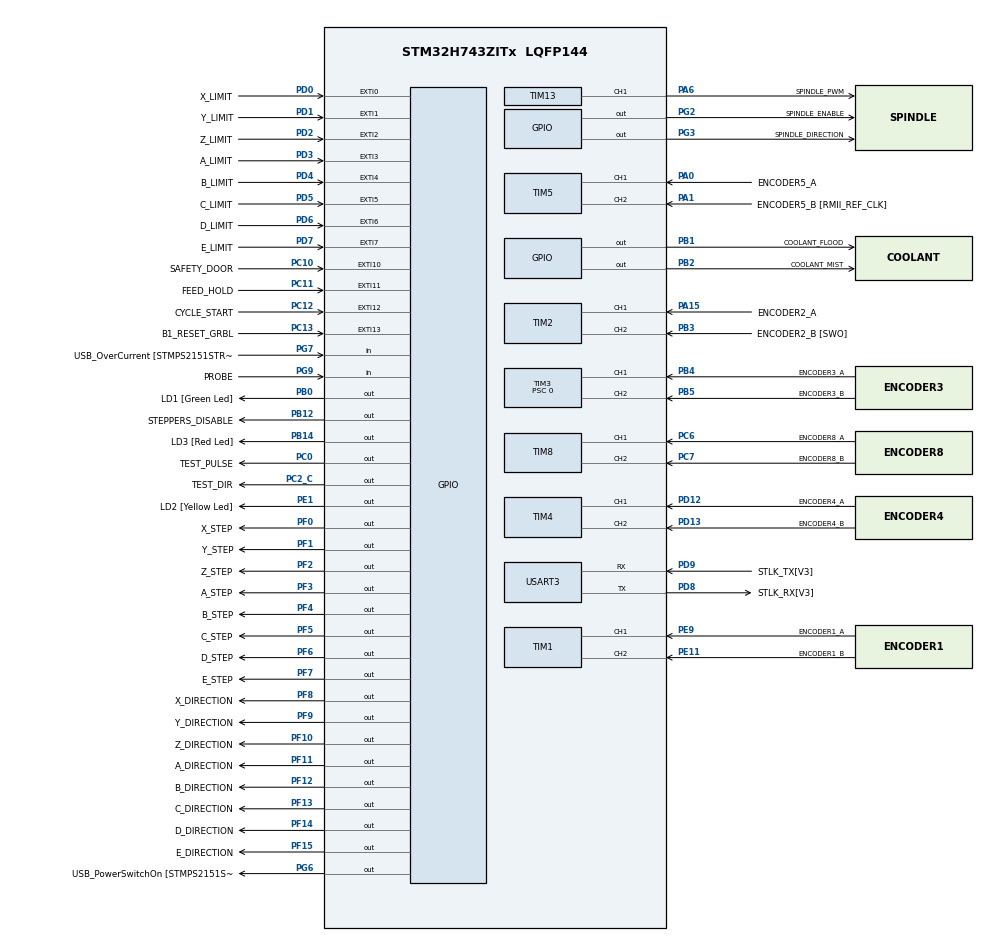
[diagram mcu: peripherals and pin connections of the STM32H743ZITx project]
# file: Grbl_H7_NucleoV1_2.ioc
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CORTEX_M7.AccessPermission-Cortex_Memory_Protection_Unit_Region0_Settings=MPU_REGION_PRIV_RW_URO
CORTEX_M7.BaseAddress-Cortex_Memory_Protection_Unit_Region0_Settings=0x38800000
CORTEX_M7.CPU_DCache=Enabled
CORTEX_M7.CPU_ICache=Enabled
CORTEX_M7.Enable-Cortex_Memory_Protection_Unit_Region0_Settings=MPU_REGION_ENABLE
CORTEX_M7.IsBufferable-Cortex_Memory_Protection_Unit_Region0_Settings=MPU_ACCESS_BUFFERABLE
CORTEX_M7.IsCacheable-Cortex_Memory_Protection_Unit_Region0_Settings=MPU_ACCESS_CACHEABLE
CORTEX_M7.IsShareable-Cortex_Memory_Protection_Unit_Region0_Settings=MPU_ACCESS_SHAREABLE
CORTEX_M7.MPU_Control=MPU_HFNMI_PRIVDEF
CORTEX_M7.Size-Cortex_Memory_Protection_Unit_Region0_Settings=MPU_REGION_SIZE_4KB
Mcu.Family=STM32H7
Mcu.Name=STM32H743ZITx
Mcu.Package=LQFP144
NVIC.EXTI0_IRQn=true\:1\:0\:true\:false\:true\:true\:true
NVIC.EXTI15_10_IRQn=true\:8\:0\:true\:false\:true\:true\:true
NVIC.EXTI1_IRQn=true\:1\:0\:true\:false\:true\:true\:true
NVIC.EXTI2_IRQn=true\:1\:0\:true\:false\:true\:true\:true
NVIC.EXTI3_IRQn=true\:1\:0\:true\:false\:true\:true\:true
NVIC.EXTI4_IRQn=true\:1\:0\:true\:false\:true\:true\:true
NVIC.EXTI9_5_IRQn=true\:1\:0\:true\:false\:true\:true\:true
NVIC.PriorityGroup=NVIC_PRIORITYGROUP_4
NVIC.RCC_IRQn=true\:0\:0\:true\:false\:true\:true\:false
NVIC.TIM1_UP_IRQn=true\:0\:0\:true\:false\:true\:true\:true
NVIC.TIM3_IRQn=true\:0\:0\:true\:false\:true\:true\:true
NVIC.TIM4_IRQn=true\:0\:0\:false\:false\:true\:true\:true
NVIC.TIM8_BRK_TIM12_IRQn=true\:6\:0\:true\:false\:true\:true\:true
NVIC.TIM8_TRG_COM_TIM14_IRQn=true\:5\:0\:true\:false\:true\:true\:true
NVIC.TIM8_UP_TIM13_IRQn=true\:0\:0\:false\:false\:true\:true\:true
NVIC.USART3_IRQn=true\:7\:0\:true\:false\:true\:true\:true
PA0.GPIO_Label=ENCODER5_A
PA0.GPIO_PuPd=GPIO_PULLUP
PA0.GPIO_Speed=GPIO_SPEED_FREQ_VERY_HIGH
PA0.Signal=S_TIM5_CH1
PA1.GPIO_Label=ENCODER5_B [RMII_REF_CLK]
PA1.GPIO_PuPd=GPIO_PULLUP
PA1.GPIO_Speed=GPIO_SPEED_FREQ_VERY_HIGH
PA1.Signal=S_TIM5_CH2
PA10.GPIO_Label=USB_ID
PA10.Signal=USB_OTG_FS_ID
PA11.GPIO_Label=USB_DM
PA11.GPIO_Speed=GPIO_SPEED_FREQ_VERY_HIGH
PA11.Signal=USB_OTG_FS_DM
PA12.GPIO_Label=USB_DP
PA12.GPIO_Speed=GPIO_SPEED_FREQ_VERY_HIGH
PA12.Signal=USB_OTG_FS_DP
PA13\ (JTMS/SWDIO).Mode=Serial_Wire
PA13\ (JTMS/SWDIO).Signal=DEBUG_JTMS-SWDIO
PA14\ (JTCK/SWCLK).Mode=Serial_Wire
PA14\ (JTCK/SWCLK).Signal=DEBUG_JTCK-SWCLK
PA15\ (JTDI).GPIO_Label=ENCODER2_A
PA15\ (JTDI).GPIO_PuPd=GPIO_PULLUP
PA15\ (JTDI).GPIO_Speed=GPIO_SPEED_FREQ_VERY_HIGH
PA15\ (JTDI).Signal=S_TIM2_CH1
PA2.GPIO_Label=RMII_MDIO
PA2.Signal=ETH_MDIO
PA6.GPIO_Label=SPINDLE_PWM
PA6.GPIO_Speed=GPIO_SPEED_FREQ_VERY_HIGH
PA6.Signal=S_TIM13_CH1
PA7.GPIO_Label=RMII_CRS_DV
PA7.Signal=ETH_CRS_DV
PA8.GPIO_Label=USB_SOF [TP1]
PA8.GPIO_Speed=GPIO_SPEED_FREQ_VERY_HIGH
PA8.Signal=USB_OTG_FS_SOF
PA9.GPIO_Label=USB_VBUS
PA9.Signal=USB_OTG_FS_VBUS
PB0.GPIO_Label=LD1 [Green Led]
PB0.GPIO_Speed=GPIO_SPEED_FREQ_VERY_HIGH
PB0.Signal=GPIO_Output
PB1.GPIO_Label=COOLANT_FLOOD
PB1.GPIO_Speed=GPIO_SPEED_FREQ_VERY_HIGH
PB1.Signal=GPIO_Output
PB12.GPIO_Label=STEPPERS_DISABLE
PB12.GPIO_Speed=GPIO_SPEED_FREQ_VERY_HIGH
PB12.Signal=GPIO_Output
PB13.GPIO_Label=RMII_TXD1
PB13.Signal=ETH_TXD1
PB14.GPIO_Label=LD3 [Red Led]
PB14.GPIO_Speed=GPIO_SPEED_FREQ_VERY_HIGH
PB14.Signal=GPIO_Output
PB2.GPIO_Label=COOLANT_MIST
PB2.GPIO_Speed=GPIO_SPEED_FREQ_VERY_HIGH
PB2.Signal=GPIO_Output
PB3\ (JTDO/TRACESWO).GPIO_Label=ENCODER2_B [SWO]
PB3\ (JTDO/TRACESWO).GPIO_PuPd=GPIO_PULLUP
PB3\ (JTDO/TRACESWO).GPIO_Speed=GPIO_SPEED_FREQ_VERY_HIGH
PB3\ (JTDO/TRACESWO).Signal=S_TIM2_CH2
PB4\ (NJTRST).GPIO_Label=ENCODER3_A
PB4\ (NJTRST).GPIO_PuPd=GPIO_PULLUP
PB4\ (NJTRST).GPIO_Speed=GPIO_SPEED_FREQ_VERY_HIGH
PB4\ (NJTRST).Signal=S_TIM3_CH1
PB5.GPIO_Label=ENCODER3_B
PB5.GPIO_PuPd=GPIO_PULLUP
PB5.GPIO_Speed=GPIO_SPEED_FREQ_VERY_HIGH
PB5.Signal=S_TIM3_CH2
PC0.GPIO_Label=TEST_PULSE
PC0.GPIO_Speed=GPIO_SPEED_FREQ_VERY_HIGH
PC0.Signal=GPIO_Output
PC1.GPIO_Label=RMII_MDC
PC1.Signal=ETH_MDC
PC10.GPIO_Label=SAFETY_DOOR
PC10.GPIO_ModeDefaultEXTI=GPIO_MODE_IT_FALLING
PC10.GPIO_PuPd=GPIO_PULLUP
PC10.Signal=GPXTI10
PC11.GPIO_Label=FEED_HOLD
PC11.GPIO_ModeDefaultEXTI=GPIO_MODE_IT_FALLING
PC11.GPIO_PuPd=GPIO_PULLUP
PC11.Signal=GPXTI11
PC12.GPIO_Label=CYCLE_START
PC12.GPIO_ModeDefaultEXTI=GPIO_MODE_IT_FALLING
PC12.GPIO_PuPd=GPIO_PULLUP
PC12.Signal=GPXTI12
PC13.GPIO_Label=B1_RESET_GRBL
PC13.GPIO_ModeDefaultEXTI=GPIO_MODE_IT_FALLING
PC13.Signal=GPXTI13
PC14-OSC32_IN\ (OSC32_IN).Mode=LSE-External-Oscillator
PC14-OSC32_IN\ (OSC32_IN).Signal=RCC_OSC32_IN
PC15-OSC32_OUT\ (OSC32_OUT).Mode=LSE-External-Oscillator
PC15-OSC32_OUT\ (OSC32_OUT).Signal=RCC_OSC32_OUT
PC2_C.GPIO_Label=TEST_DIR
PC2_C.GPIO_Speed=GPIO_SPEED_FREQ_VERY_HIGH
PC2_C.Signal=GPIO_Output
PC4.GPIO_Label=RMII_RXD0
PC4.Signal=ETH_RXD0
PC5.GPIO_Label=RMII_RXD1
PC5.Signal=ETH_RXD1
PC6.GPIO_Label=ENCODER8_A
PC6.GPIO_PuPd=GPIO_PULLUP
PC6.GPIO_Speed=GPIO_SPEED_FREQ_VERY_HIGH
PC6.Signal=S_TIM8_CH1
PC7.GPIO_Label=ENCODER8_B
PC7.GPIO_PuPd=GPIO_PULLUP
PC7.GPIO_Speed=GPIO_SPEED_FREQ_VERY_HIGH
PC7.Signal=S_TIM8_CH2
PD0.GPIO_Label=X_LIMIT
PD0.GPIO_ModeDefaultEXTI=GPIO_MODE_IT_RISING_FALLING
PD0.GPIO_PuPd=GPIO_PULLUP
PD0.Signal=GPXTI0
PD1.GPIO_Label=Y_LIMIT
PD1.GPIO_ModeDefaultEXTI=GPIO_MODE_IT_RISING_FALLING
PD1.GPIO_PuPd=GPIO_PULLUP
PD1.Signal=GPXTI1
PD12.GPIO_Label=ENCODER4_A
PD12.GPIO_PuPd=GPIO_PULLUP
PD12.GPIO_Speed=GPIO_SPEED_FREQ_VERY_HIGH
PD12.Signal=S_TIM4_CH1
PD13.GPIO_Label=ENCODER4_B
PD13.GPIO_PuPd=GPIO_PULLUP
PD13.GPIO_Speed=GPIO_SPEED_FREQ_VERY_HIGH
PD13.Signal=S_TIM4_CH2
PD2.GPIO_Label=Z_LIMIT
PD2.GPIO_ModeDefaultEXTI=GPIO_MODE_IT_RISING_FALLING
PD2.GPIO_PuPd=GPIO_PULLUP
PD2.Signal=GPXTI2
PD3.GPIO_Label=A_LIMIT
PD3.GPIO_ModeDefaultEXTI=GPIO_MODE_IT_RISING_FALLING
PD3.GPIO_PuPd=GPIO_PULLUP
PD3.Signal=GPXTI3
PD4.GPIO_Label=B_LIMIT
PD4.GPIO_ModeDefaultEXTI=GPIO_MODE_IT_RISING_FALLING
PD4.GPIO_PuPd=GPIO_PULLUP
PD4.Signal=GPXTI4
PD5.GPIO_Label=C_LIMIT
PD5.GPIO_ModeDefaultEXTI=GPIO_MODE_IT_RISING_FALLING
PD5.GPIO_PuPd=GPIO_PULLUP
PD5.Signal=GPXTI5
PD6.GPIO_Label=D_LIMIT
PD6.GPIO_PuPd=GPIO_PULLUP
PD6.Signal=GPXTI6
PD7.GPIO_Label=E_LIMIT
PD7.GPIO_PuPd=GPIO_PULLUP
PD7.Signal=GPXTI7
PD8.GPIO_Label=STLK_RX[V3]
PD8.GPIO_Speed=GPIO_SPEED_FREQ_VERY_HIGH
PD8.Mode=Asynchronous
PD8.Signal=USART3_TX
PD9.GPIO_Label=STLK_TX[V3]
PD9.GPIO_Speed=GPIO_SPEED_FREQ_VERY_HIGH
PD9.Mode=Asynchronous
PD9.Signal=USART3_RX
PE1.GPIO_Label=LD2 [Yellow Led]
PE1.Signal=GPIO_Output
PE11.GPIO_Label=ENCODER1_B
PE11.GPIO_PuPd=GPIO_PULLUP
PE11.GPIO_Speed=GPIO_SPEED_FREQ_VERY_HIGH
PE11.Signal=S_TIM1_CH2
PE9.GPIO_Label=ENCODER1_A
PE9.GPIO_PuPd=GPIO_PULLUP
PE9.GPIO_Speed=GPIO_SPEED_FREQ_VERY_HIGH
PE9.Signal=S_TIM1_CH1
PF0.GPIO_Label=X_STEP
PF0.GPIO_Speed=GPIO_SPEED_FREQ_VERY_HIGH
PF0.Signal=GPIO_Output
PF1.GPIO_Label=Y_STEP
PF1.GPIO_Speed=GPIO_SPEED_FREQ_VERY_HIGH
PF1.Signal=GPIO_Output
PF10.GPIO_Label=Z_DIRECTION
PF10.GPIO_Speed=GPIO_SPEED_FREQ_VERY_HIGH
PF10.Signal=GPIO_Output
PF11.GPIO_Label=A_DIRECTION
PF11.GPIO_Speed=GPIO_SPEED_FREQ_VERY_HIGH
PF11.Signal=GPIO_Output
PF12.GPIO_Label=B_DIRECTION
PF12.GPIO_Speed=GPIO_SPEED_FREQ_VERY_HIGH
PF12.Signal=GPIO_Output
PF13.GPIO_Label=C_DIRECTION
PF13.GPIO_Speed=GPIO_SPEED_FREQ_VERY_HIGH
PF13.Signal=GPIO_Output
PF14.GPIO_Label=D_DIRECTION
PF14.GPIO_Speed=GPIO_SPEED_FREQ_VERY_HIGH
PF14.Signal=GPIO_Output
PF15.GPIO_Label=E_DIRECTION
PF15.GPIO_Speed=GPIO_SPEED_FREQ_VERY_HIGH
PF15.Signal=GPIO_Output
PF2.GPIO_Label=Z_STEP
PF2.GPIO_Speed=GPIO_SPEED_FREQ_VERY_HIGH
PF2.Signal=GPIO_Output
PF3.GPIO_Label=A_STEP
PF3.GPIO_Speed=GPIO_SPEED_FREQ_VERY_HIGH
PF3.Signal=GPIO_Output
PF4.GPIO_Label=B_STEP
PF4.GPIO_Speed=GPIO_SPEED_FREQ_VERY_HIGH
PF4.Signal=GPIO_Output
PF5.GPIO_Label=C_STEP
PF5.GPIO_Speed=GPIO_SPEED_FREQ_VERY_HIGH
PF5.Signal=GPIO_Output
PF6.GPIO_Label=D_STEP
PF6.GPIO_Speed=GPIO_SPEED_FREQ_VERY_HIGH
PF6.Signal=GPIO_Output
PF7.GPIO_Label=E_STEP
PF7.GPIO_Speed=GPIO_SPEED_FREQ_VERY_HIGH
PF7.Signal=GPIO_Output
PF8.GPIO_Label=X_DIRECTION
PF8.GPIO_Speed=GPIO_SPEED_FREQ_VERY_HIGH
PF8.Signal=GPIO_Output
PF9.GPIO_Label=Y_DIRECTION
PF9.GPIO_Speed=GPIO_SPEED_FREQ_VERY_HIGH
PF9.Signal=GPIO_Output
PG11.GPIO_Label=RMII_TX_EN
PG11.Signal=ETH_TX_EN
PG13.GPIO_Label=RMII_TXD0
PG13.Signal=ETH_TXD0
PG2.GPIO_Label=SPINDLE_ENABLE
PG2.GPIO_Speed=GPIO_SPEED_FREQ_VERY_HIGH
PG2.Signal=GPIO_Output
PG3.GPIO_Label=SPINDLE_DIRECTION
PG3.GPIO_Speed=GPIO_SPEED_FREQ_VERY_HIGH
PG3.Signal=GPIO_Output
PG6.GPIO_Label=USB_PowerSwitchOn [STMPS2151STR_EN]
PG6.GPIO_Speed=GPIO_SPEED_FREQ_VERY_HIGH
PG6.Signal=GPIO_Output
PG7.GPIO_Label=USB_OverCurrent [STMPS2151STR_FAULT]
PG7.Signal=GPIO_Input
PG9.GPIO_Label=PROBE
PG9.GPIO_PuPd=GPIO_PULLUP
PG9.Signal=GPIO_Input
PH0-OSC_IN\ (PH0).GPIO_Label=MCO
PH0-OSC_IN\ (PH0).Mode=HSE-External-Clock-Source
PH0-OSC_IN\ (PH0).Signal=RCC_OSC_IN
PH1-OSC_OUT\ (PH1).Signal=RCC_OSC_OUT
ProjectManager.HeapSize=0x400
ProjectManager.StackSize=0x800
ProjectManager.TargetToolchain=STM32CubeIDE
RCC.48MHZClocksFreq_Value=24000000
RCC.ADCFreq_Value=96000000
RCC.AHBFreq_Value=216000000
RCC.APB1CLKDivider=RCC_HCLK_DIV4
RCC.APB1Freq_Value=100000000
RCC.APB1TimFreq_Value=108000000
RCC.APB2CLKDivider=RCC_HCLK_DIV2
RCC.APB2Freq_Value=100000000
RCC.APB2TimFreq_Value=216000000
RCC.APB3Freq_Value=100000000
RCC.APB4Freq_Value=100000000
RCC.CortexFreq_Value=400000000
RCC.D1PPRE=RCC_APB3_DIV2
RCC.D2PPRE1=RCC_APB1_DIV2
RCC.D2PPRE2=RCC_APB2_DIV2
RCC.D3PPRE=RCC_APB4_DIV2
RCC.DIVM1=4
RCC.DIVM2=8
RCC.DIVM3=8
RCC.DIVN1=400
RCC.DIVN2=192
RCC.DIVN3=192
RCC.DIVQ2=4
RCC.DIVQ3=4
RCC.EnbaleCSS=true
RCC.HCLKFreq_Value=200000000
RCC.HPRE=RCC_HCLK_DIV2
RCC.HSE_VALUE=8000000
RCC.HSI_VALUE=64000000
RCC.PLLM=25
RCC.PLLMUL=RCC_PLL_MUL9
RCC.PLLN=432
RCC.PLLQ=9
RCC.PLLSourceVirtual=RCC_PLLSOURCE_HSE
RCC.PRESCALERUSB=RCC_USBCLKSOURCE_PLL_DIV1_5
RCC.PWR_Regulator_Voltage_Scale=PWR_REGULATOR_VOLTAGE_SCALE1
RCC.SYSCLKFreq_VALUE=400000000
RCC.SYSCLKSource=RCC_SYSCLKSOURCE_PLLCLK
RCC.SYSCLKSourceVirtual=RCC_SYSCLKSOURCE_PLLCLK
RCC.USART234578CLockSelection=RCC_USART234578CLKSOURCE_PLL3
RCC.USBCLockSelection=RCC_USBCLKSOURCE_PLL3
RCC.USBFreq_Value=48000000
RCC.VCOOutputFreq_Value=432000000
SH.S_TIM13_CH1.0=TIM13_CH1,PWM Generation1 CH1
SH.S_TIM1_CH1.0=TIM1_CH1,Encoder_Interface
SH.S_TIM1_CH2.0=TIM1_CH2,Encoder_Interface
SH.S_TIM2_CH1.0=TIM2_CH1,Encoder_Interface
SH.S_TIM2_CH2.0=TIM2_CH2,Encoder_Interface
SH.S_TIM3_CH1.0=TIM3_CH1,Encoder_Interface
SH.S_TIM3_CH2.0=TIM3_CH2,Encoder_Interface
SH.S_TIM4_CH1.0=TIM4_CH1,Encoder_Interface
SH.S_TIM4_CH2.0=TIM4_CH2,Encoder_Interface
SH.S_TIM5_CH1.0=TIM5_CH1,Encoder_Interface
SH.S_TIM5_CH2.0=TIM5_CH2,Encoder_Interface
SH.S_TIM8_CH1.0=TIM8_CH1,Encoder_Interface
SH.S_TIM8_CH2.0=TIM8_CH2,Encoder_Interface
TIM12.Period=0
TIM13.Channel=TIM_CHANNEL_1
TIM3.IC1Filter=0
TIM3.IC2Filter=0
TIM3.Period=0
TIM3.Prescaler=0
TIM6.Period=0
TIM6.Prescaler=0
USART3.VirtualMode-Asynchronous=VM_ASYNC
USART3.WordLength=WORDLENGTH_8B
VP_RTC_VS_RTC_Activate.Mode=RTC_Enabled
VP_TIM12_VS_ClockSourceINT.Mode=Internal
VP_TIM13_VS_ClockSourceINT.Mode=Enable_Timer
VP_TIM14_VS_ClockSourceINT.Mode=Enable_Timer
VP_TIM6_VS_ClockSourceINT.Mode=Enable_Timer
VP_TIM7_VS_ClockSourceINT.Mode=Enable_Timer
board=NUCLEO-H743ZI

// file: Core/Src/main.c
/* USER CODE BEGIN Header */
/**
  ******************************************************************************
  * @file           : main.c
  * @brief          : Main program body
  ******************************************************************************
  ** This notice applies to any and all portions of this file
  * that are not between comment pairs USER CODE BEGIN and
  * USER CODE END. Other portions of this file, whether
  * inserted by the user or by software development tools
  * are owned by their respective copyright owners.
  *
  * COPYRIGHT(c) 2018 STMicroelectronics
  *
  * Redistribution and use in source and binary forms, with or without modification,
  * are permitted provided that the following conditions are met:
  *   1. Redistributions of source code must retain the above copyright notice,
  *      this list of conditions and the following disclaimer.
  *   2. Redistributions in binary form must reproduce the above copyright notice,
  *      this list of conditions and the following disclaimer in the documentation
  *      and/or other materials provided with the distribution.
  *   3. Neither the name of STMicroelectronics nor the names of its contributors
  *      may be used to endorse or promote products derived from this software
  *      without specific prior written permission.
  *
  * THIS SOFTWARE IS PROVIDED BY THE COPYRIGHT HOLDERS AND CONTRIBUTORS "AS IS"
  * AND ANY EXPRESS OR IMPLIED WARRANTIES, INCLUDING, BUT NOT LIMITED TO, THE
  * IMPLIED WARRANTIES OF MERCHANTABILITY AND FITNESS FOR A PARTICULAR PURPOSE ARE
  * DISCLAIMED. IN NO EVENT SHALL THE COPYRIGHT HOLDER OR CONTRIBUTORS BE LIABLE
  * FOR ANY DIRECT, INDIRECT, INCIDENTAL, SPECIAL, EXEMPLARY, OR CONSEQUENTIAL
  * DAMAGES (INCLUDING, BUT NOT LIMITED TO, PROCUREMENT OF SUBSTITUTE GOODS OR
  * SERVICES; LOSS OF USE, DATA, OR PROFITS; OR BUSINESS INTERRUPTION) HOWEVER
  * CAUSED AND ON ANY THEORY OF LIABILITY, WHETHER IN CONTRACT, STRICT LIABILITY,
  * OR TORT (INCLUDING NEGLIGENCE OR OTHERWISE) ARISING IN ANY WAY OUT OF THE USE
  * OF THIS SOFTWARE, EVEN IF ADVISED OF THE POSSIBILITY OF SUCH DAMAGE.
  *
  ******************************************************************************
  */
/* USER CODE END Header */

#include "main.h"

/* USER CODE BEGIN Includes */
#include "Extern_Variables_functions.h"
/* USER CODE END Includes */

RTC_HandleTypeDef hrtc;

TIM_HandleTypeDef htim1;
TIM_HandleTypeDef htim2;
TIM_HandleTypeDef htim3;
TIM_HandleTypeDef htim4;
TIM_HandleTypeDef htim5;
TIM_HandleTypeDef htim6;
TIM_HandleTypeDef htim7;
TIM_HandleTypeDef htim8;
TIM_HandleTypeDef htim13;

UART_HandleTypeDef huart3;

/* USER CODE BEGIN PV */
/* Private variables ---------------------------------------------------------*/
// Declare system global variable structure
  system_t sys;
  int32_t sys_position[N_AXIS];      // Real-time machine (aka home) position vector in steps.
  int32_t sys_probe_position[N_AXIS]; // Last probe position in machine coordinates and steps.
#ifdef USER_NON_VOLATILE
  uint8_t sys_probe_state;   // Probing state value.  Used to coordinate the probing cycle with stepper ISR.
  uint8_t sys_rt_exec_state;   // Global realtime executor bitflag variable for state management. See EXEC bitmasks.
  uint8_t sys_rt_exec_alarm;   // Global realtime executor bitflag variable for setting various alarms
  #ifdef USER_RAPID_OVR_HIGH
    uint16_t sys_rt_exec_motion_override; // Global realtime executor bitflag variable for motion-based overrides.
  #else
    uint8_t sys_rt_exec_motion_override; // Global realtime executor bitflag variable for motion-based overrides.
  #endif
  uint8_t sys_rt_exec_accessory_override; // Global realtime executor bitflag variable for spindle/coolant overrides.
#else
  volatile uint8_t sys_probe_state;   // Probing state value.  Used to coordinate the probing cycle with stepper ISR.
  volatile uint8_t sys_rt_exec_state;   // Global realtime executor bitflag variable for state management. See EXEC bitmasks.
  volatile uint8_t sys_rt_exec_alarm;   // Global realtime executor bitflag variable for setting various alarms
  #ifdef USER_RAPID_OVR_HIGH
    volatile uint16_t sys_rt_exec_motion_override; // Global realtime executor bitflag variable for motion-based overrides.
  #else
    volatile uint8_t sys_rt_exec_motion_override; // Global realtime executor bitflag variable for motion-based overrides.
  #endif
  volatile uint8_t sys_rt_exec_accessory_override; // Global realtime executor bitflag variable for spindle/coolant overrides.
#endif
  #ifdef USER_MORE_AXIS
    #ifdef USER_6_AXIS
      #ifdef USER_8_AXIS
        uint8_t DirectionBitSimulateArray[N_AXIS]={X_DIRECTION_BIT_SIMULATE_INDEX, Y_DIRECTION_BIT_SIMULATE_INDEX, Z_DIRECTION_BIT_SIMULATE_INDEX,
            A_DIRECTION_BIT_SIMULATE_INDEX, B_DIRECTION_BIT_SIMULATE_INDEX, C_DIRECTION_BIT_SIMULATE_INDEX,
            D_DIRECTION_BIT_SIMULATE_INDEX, E_DIRECTION_BIT_SIMULATE_INDEX};
        uint8_t StepBitSimulateArray[N_AXIS]={X_STEP_BIT_SIMULATE_INDEX, Y_STEP_BIT_SIMULATE_INDEX,Z_STEP_BIT_SIMULATE_INDEX, A_STEP_BIT_SIMULATE_INDEX,
            B_STEP_BIT_SIMULATE_INDEX, C_STEP_BIT_SIMULATE_INDEX, D_STEP_BIT_SIMULATE_INDEX, E_STEP_BIT_SIMULATE_INDEX};
        uint8_t LimitBitSimulateArray[N_AXIS] = {X_LIMIT_PIN_INDEX, Y_LIMIT_PIN_INDEX, Z_LIMIT_PIN_INDEX, A_LIMIT_PIN_INDEX,
            B_LIMIT_PIN_INDEX, C_LIMIT_PIN_INDEX, D_LIMIT_PIN_INDEX, E_LIMIT_PIN_INDEX};
      #else //USER_6_AXIS
            uint8_t DirectionBitSimulateArray[N_AXIS]={X_DIRECTION_BIT_SIMULATE_INDEX, Y_DIRECTION_BIT_SIMULATE_INDEX, Z_DIRECTION_BIT_SIMULATE_INDEX,
                A_DIRECTION_BIT_SIMULATE_INDEX, B_DIRECTION_BIT_SIMULATE_INDEX, C_DIRECTION_BIT_SIMULATE_INDEX};
            uint8_t StepBitSimulateArray[N_AXIS]={X_STEP_BIT_SIMULATE_INDEX, Y_STEP_BIT_SIMULATE_INDEX,Z_STEP_BIT_SIMULATE_INDEX, A_STEP_BIT_SIMULATE_INDEX,
                B_STEP_BIT_SIMULATE_INDEX, C_STEP_BIT_SIMULATE_INDEX};
            uint8_t LimitBitSimulateArray[N_AXIS] = {X_LIMIT_PIN_INDEX, Y_LIMIT_PIN_INDEX, Z_LIMIT_PIN_INDEX, A_LIMIT_PIN_INDEX,
                B_LIMIT_PIN_INDEX, C_LIMIT_PIN_INDEX};
      #endif
    #else //USER_4_AXIS
      uint8_t DirectionBitSimulateArray[N_AXIS]={X_DIRECTION_BIT_SIMULATE_INDEX, Y_DIRECTION_BIT_SIMULATE_INDEX, Z_DIRECTION_BIT_SIMULATE_INDEX, A_DIRECTION_BIT_SIMULATE_INDEX};
      uint8_t StepBitSimulateArray[N_AXIS]={X_STEP_BIT_SIMULATE_INDEX, Y_STEP_BIT_SIMULATE_INDEX,Z_STEP_BIT_SIMULATE_INDEX, A_STEP_BIT_SIMULATE_INDEX};
      uint8_t LimitBitSimulateArray[N_AXIS] = {X_LIMIT_PIN_INDEX, Y_LIMIT_PIN_INDEX, Z_LIMIT_PIN_INDEX, A_LIMIT_PIN_INDEX};
    #endif
  #else
    uint8_t DirectionBitSimulateArray[N_AXIS]={X_DIRECTION_BIT_SIMULATE_INDEX, Y_DIRECTION_BIT_SIMULATE_INDEX, Z_DIRECTION_BIT_SIMULATE_INDEX};
    uint8_t StepBitSimulateArray[N_AXIS]={X_STEP_BIT_SIMULATE_INDEX, Y_STEP_BIT_SIMULATE_INDEX,Z_STEP_BIT_SIMULATE_INDEX};
    uint8_t LimitBitSimulateArray[N_AXIS] = {X_LIMIT_PIN_INDEX, Y_LIMIT_PIN_INDEX, Z_LIMIT_PIN_INDEX};
  #endif // USER_MORE_AXIS

#ifdef DEBUG
  volatile uint8_t sys_rt_exec_debug;
#endif
#ifdef STM32H743xx
  /* Backup registers table */
  uint32_t aBKPDataReg[RTC_BKP_NUMBER] =
  {
    RTC_BKP_DR0,  RTC_BKP_DR1,  RTC_BKP_DR2,
    RTC_BKP_DR3,  RTC_BKP_DR4,  RTC_BKP_DR5,
    RTC_BKP_DR6,  RTC_BKP_DR7,  RTC_BKP_DR8,
    RTC_BKP_DR9,  RTC_BKP_DR10, RTC_BKP_DR11,
    RTC_BKP_DR12, RTC_BKP_DR13, RTC_BKP_DR14,
    RTC_BKP_DR15, RTC_BKP_DR16, RTC_BKP_DR17,
    RTC_BKP_DR18, RTC_BKP_DR19, RTC_BKP_DR20,
    RTC_BKP_DR21, RTC_BKP_DR22, RTC_BKP_DR23,
    RTC_BKP_DR24, RTC_BKP_DR25, RTC_BKP_DR26,
    RTC_BKP_DR27, RTC_BKP_DR28, RTC_BKP_DR29,
    RTC_BKP_DR30, RTC_BKP_DR31
  };
#else
  #define RTC_BKP_DR_NUMBER   0x14
  uint32_t aBKPDataReg[RTC_BKP_DR_NUMBER] =
    {
      RTC_BKP_DR0, RTC_BKP_DR1, RTC_BKP_DR2,
      RTC_BKP_DR3, RTC_BKP_DR4, RTC_BKP_DR5,
      RTC_BKP_DR6, RTC_BKP_DR7, RTC_BKP_DR8,
      RTC_BKP_DR9, RTC_BKP_DR10, RTC_BKP_DR11,
      RTC_BKP_DR12, RTC_BKP_DR13, RTC_BKP_DR14,
      RTC_BKP_DR15, RTC_BKP_DR16, RTC_BKP_DR17,
      RTC_BKP_DR18,  RTC_BKP_DR19
    };
#endif

  #ifdef USER_SAVE_BACKLASH
    extern plan_block_backlash_t block_backlash ;
  #endif //USER_SAVE_BACKLASH
/* USER CODE END PV */

void SystemClock_Config(void);
static void MPU_Config(void);
static void MX_GPIO_Init(void);
static void MX_RTC_Init(void);
static void MX_TIM6_Init(void);
static void MX_USART3_UART_Init(void);
static void MX_TIM3_Init(void);
static void MX_TIM12_Init(void);
static void MX_TIM7_Init(void);
static void MX_TIM13_Init(void);
static void MX_TIM14_Init(void);
static void MX_TIM2_Init(void);
static void MX_TIM4_Init(void);
static void MX_TIM1_Init(void);
static void MX_TIM5_Init(void);
static void MX_TIM8_Init(void);
/* USER CODE BEGIN PFP */
/* Private function prototypes -----------------------------------------------*/

/* USER CODE END PFP */

int main(void)
{
  /* USER CODE BEGIN 1 */
//  HAL_PWR_EnableBkUpAccess();// in SystemClock_Config()
  /* USER CODE END 1 */

  /* MPU Configuration--------------------------------------------------------*/
  MPU_Config();

  /* Enable I-Cache---------------------------------------------------------*/
  SCB_EnableICache();

  /* Enable D-Cache---------------------------------------------------------*/
  SCB_EnableDCache();

  /* MCU Configuration--------------------------------------------------------*/

  /* Reset of all peripherals, Initializes the Flash interface and the Systick. */
  HAL_Init();

  /* Configure the system clock */
  SystemClock_Config();

  /* USER CODE BEGIN SysInit */
  /* USER CODE END TIM1_MspPostInit 0 */

  /* USER CODE END SysInit */

  /* Initialize all configured peripherals */
  MX_GPIO_Init();
  MX_RTC_Init();
  MX_TIM6_Init();
  MX_USART3_UART_Init();
  MX_TIM3_Init();
  MX_TIM12_Init();
  MX_TIM7_Init();
  MX_TIM13_Init();
  MX_TIM14_Init();
  MX_TIM2_Init();
  MX_TIM4_Init();
  MX_TIM1_Init();
  MX_TIM5_Init();
  MX_TIM8_Init();
  /* USER CODE BEGIN 2 */

  HAL_PWREx_EnableBkUpReg();
  #ifdef STM32H743xx
    __HAL_RCC_BACKUPRESET_RELEASE();

    __HAL_RCC_BKPRAM_CLK_ENABLE();
    __HAL_RCC_BKPRAM_CLKAM_ENABLE();
    __HAL_RCC_BKPRAM_CLK_SLEEP_ENABLE();

    __HAL_RCC_RTC_CLK_ENABLE();
    __HAL_RCC_RTC_CLKAM_ENABLE();
    __HAL_RCC_RTC_CLK_SLEEP_ENABLE();

  #else
    __HAL_RCC_BKPSRAM_CLK_ENABLE();
  #endif

  Delay_Init();
  EncoderInit();
  // Initialize system upon power-up.
  serial_init();   // Setup serial baud rate and interrupts
  settings_init(); // Load Grbl settings from EEPROM
  stepper_init();  // Configure stepper pins and interrupt timers
  system_init();   // Configure pinout pins and pin-change interrupt

//  HAL_SuspendTick();
  memset(sys_position,0,sizeof(sys_position)); // Clear machine position.

  #ifdef USER_SAVE_POSITION
    __IO uint8_t idxMain;
    for (idxMain = 0; idxMain < N_AXIS; idxMain++)
    {
      sys_position[idxMain] = BufferBackupRTC32[idxMain];
    }
  #endif //USER_SAVE_POSITION
  #ifdef USER_SAVE_BACKLASH
    for (idxMain = 0; idxMain < N_AXIS; idxMain++)
    {
      block_backlash.direction_state[idxMain] = BufferBackupRTC8[idxMain];
    }
  #endif

  sei(); // Enable interrupts

  // Initialize system state.
  #ifdef FORCE_INITIALIZATION_ALARM
    // Force Grbl into an ALARM state upon a power-cycle or hard reset.
    sys.state = STATE_ALARM;
  #else
    sys.state = STATE_IDLE;
  #endif

  // Check for power-up and set system alarm if homing is enabled to force homing cycle
  // by setting Grbl's alarm state. Alarm locks out all g-code commands, including the
  // startup scripts, but allows access to settings and internal commands. Only a homing
  // cycle '$H' or kill alarm locks '$X' will disable the alarm.
  // NOTE: The startup script will run after successful completion of the homing cycle, but
  // not after disabling the alarm locks. Prevents motion startup blocks from crashing into
  // things uncontrollably. Very bad.
  #ifdef HOMING_INIT_LOCK
    if (bit_istrue(settings.flags,BITFLAG_HOMING_ENABLE)) { sys.state = STATE_ALARM; }
  #endif

  // Grbl initialization loop upon power-up or a system abort. For the latter, all processes
  // will return to this loop to be cleanly re-initialized.
  for(;;) {

    // Reset system variables.
    uint8_t prior_state = sys.state;
    memset(&sys, 0, sizeof(system_t)); // Clear system struct variable.
    sys.state = prior_state;
    sys.f_override = DEFAULT_FEED_OVERRIDE;  // Set to 100%
    sys.r_override = DEFAULT_RAPID_OVERRIDE; // Set to 100%
    sys.spindle_speed_ovr = DEFAULT_SPINDLE_SPEED_OVERRIDE; // Set to 100%
    memset(sys_probe_position,0,sizeof(sys_probe_position)); // Clear probe position.
    sys_probe_state = 0;
    sys_rt_exec_state = 0;
    sys_rt_exec_alarm = 0;
    sys_rt_exec_motion_override = 0;
    sys_rt_exec_accessory_override = 0;

    // Reset Grbl primary systems.
    serial_reset_read_buffer(); // Clear serial read buffer
    gc_init(); // Set g-code parser to default state
    spindle_init();
    coolant_init();
    limits_init();
    probe_init();
    plan_reset(); // Clear block buffer and planner variables
    st_reset(); // Clear stepper subsystem variables.

    // Sync cleared gcode and planner positions to current system position.
    plan_sync_position();
    gc_sync_position();

    // Print welcome message. Indicates an initialization has occured at power-up or with a reset.
    report_init_message();

    //__HAL_GPIO_SET_BITS(LD1_GPIO_Port, LD1_Pin);
    LL_GPIO_SetOutputPin(LD1_GPIO_Port, LD1_Pin);

    delay_ms(100);

    //__HAL_GPIO_RESET_BITS(LD1_GPIO_Port, LD1_Pin);
    LL_GPIO_ResetOutputPin(LD1_GPIO_Port, LD1_Pin);

    // Start Grbl main loop. Processes program inputs and executes them.
    protocol_main_loop();
    #ifdef USER_UNLOCK_AFTER_RESET
      // Disable alarm lock [ALARM]
      if (sys.state == STATE_ALARM) {
        report_feedback_message(MESSAGE_ALARM_UNLOCK);
        sys.state = STATE_IDLE;
        system_clear_exec_alarm(); // Clear all alarm flags
      }
    #endif

  }
  return 0;   /* Never reached */
  /* USER CODE END 2 */

  /* Infinite loop */
  while (1)
  {

  }
}

void SystemClock_Config(void)
{
  LL_FLASH_SetLatency(LL_FLASH_LATENCY_2);

   if(LL_FLASH_GetLatency() != LL_FLASH_LATENCY_2)
  {
    Error_Handler();
  }
  LL_PWR_ConfigSupply(LL_PWR_LDO_SUPPLY);
  LL_PWR_SetRegulVoltageScaling(LL_PWR_REGU_VOLTAGE_SCALE1);
  LL_RCC_HSE_EnableBypass();
  LL_RCC_HSE_Enable();

   /* Wait till HSE is ready */
  while(LL_RCC_HSE_IsReady() != 1)
  {

  }
  LL_RCC_LSI_Enable();

   /* Wait till LSI is ready */
  while(LL_RCC_LSI_IsReady() != 1)
  {

  }
  LL_PWR_EnableBkUpAccess();
  LL_RCC_ForceBackupDomainReset();
  LL_RCC_ReleaseBackupDomainReset();
  LL_RCC_EnableRTC();
  LL_RCC_HSE_EnableCSS();
  LL_RCC_PLL_SetSource(LL_RCC_PLLSOURCE_HSE);
  LL_RCC_PLL1P_Enable();
  LL_RCC_PLL1R_Enable();
  LL_RCC_PLL1_SetVCOInputRange(LL_RCC_PLLINPUTRANGE_2_4);
  LL_RCC_PLL1_SetVCOOutputRange(LL_RCC_PLLVCORANGE_WIDE);
  LL_RCC_PLL1_SetM(4);
  LL_RCC_PLL1_SetN(400);
  LL_RCC_PLL1_SetP(2);
  LL_RCC_PLL1_SetQ(2);
  LL_RCC_PLL1_SetR(2);
  LL_RCC_PLL1_Enable();

   /* Wait till PLL is ready */
  while(LL_RCC_PLL1_IsReady() != 1)
  {
  };

  LL_RCC_PLL3Q_Enable();
  LL_RCC_PLL3_SetVCOInputRange(LL_RCC_PLLINPUTRANGE_1_2);
  LL_RCC_PLL3_SetVCOOutputRange(LL_RCC_PLLVCORANGE_WIDE);
  LL_RCC_PLL3_SetM(8);
  LL_RCC_PLL3_SetN(192);
  LL_RCC_PLL3_SetP(2);
  LL_RCC_PLL3_SetQ(4);
  LL_RCC_PLL3_SetR(2);
  LL_RCC_PLL3_Enable();

   /* Wait till PLL is ready */
  while(LL_RCC_PLL3_IsReady() != 1)
  {
  };

   /* Intermediate AHB prescaler 2 when target frequency clock is higher than 80 MHz */
   LL_RCC_SetAHBPrescaler(LL_RCC_AHB_DIV_2);

  LL_RCC_SetSysClkSource(LL_RCC_SYS_CLKSOURCE_PLL1);
  LL_RCC_SetSysPrescaler(LL_RCC_SYSCLK_DIV_1);
  LL_RCC_SetAHBPrescaler(LL_RCC_AHB_DIV_2);
  LL_RCC_SetAPB1Prescaler(LL_RCC_APB1_DIV_2);
  LL_RCC_SetAPB2Prescaler(LL_RCC_APB2_DIV_2);
  LL_RCC_SetAPB3Prescaler(LL_RCC_APB3_DIV_2);
  LL_RCC_SetAPB4Prescaler(LL_RCC_APB4_DIV_2);
  LL_SetSystemCoreClock(400000000);

   /* Update the time base */
  if (HAL_InitTick (TICK_INT_PRIORITY) != HAL_OK)
  {
    Error_Handler();
  };
  LL_RCC_SetRTCClockSource(LL_RCC_RTC_CLKSOURCE_LSI);
  LL_RCC_SetUSARTClockSource(LL_RCC_USART234578_CLKSOURCE_PLL3Q);
  LL_RCC_HSE_EnableCSS();
}

static void MX_RTC_Init(void)
{

  /** Initialize RTC Only
  */
  hrtc.Instance = RTC;
  hrtc.Init.HourFormat = RTC_HOURFORMAT_24;
  hrtc.Init.AsynchPrediv = 127;
  hrtc.Init.SynchPrediv = 255;
  hrtc.Init.OutPut = RTC_OUTPUT_DISABLE;
  hrtc.Init.OutPutPolarity = RTC_OUTPUT_POLARITY_HIGH;
  hrtc.Init.OutPutType = RTC_OUTPUT_TYPE_OPENDRAIN;
  hrtc.Init.OutPutRemap = RTC_OUTPUT_REMAP_NONE;
  if (HAL_RTC_Init(&hrtc) != HAL_OK)
  {
    Error_Handler();
  }

}

static void MX_TIM1_Init(void)
{

  TIM_Encoder_InitTypeDef sConfig = {0};
  TIM_MasterConfigTypeDef sMasterConfig = {0};

  htim1.Instance = TIM1;
  htim1.Init.Prescaler = 0;
  htim1.Init.CounterMode = TIM_COUNTERMODE_UP;
  htim1.Init.Period = 0;
  htim1.Init.ClockDivision = TIM_CLOCKDIVISION_DIV1;
  htim1.Init.RepetitionCounter = 0;
  htim1.Init.AutoReloadPreload = TIM_AUTORELOAD_PRELOAD_DISABLE;
  sConfig.EncoderMode = TIM_ENCODERMODE_TI1;
  sConfig.IC1Polarity = TIM_ICPOLARITY_RISING;
  sConfig.IC1Selection = TIM_ICSELECTION_DIRECTTI;
  sConfig.IC1Prescaler = TIM_ICPSC_DIV1;
  sConfig.IC1Filter = 0;
  sConfig.IC2Polarity = TIM_ICPOLARITY_RISING;
  sConfig.IC2Selection = TIM_ICSELECTION_DIRECTTI;
  sConfig.IC2Prescaler = TIM_ICPSC_DIV1;
  sConfig.IC2Filter = 0;
  if (HAL_TIM_Encoder_Init(&htim1, &sConfig) != HAL_OK)
  {
    Error_Handler();
  }
  sMasterConfig.MasterOutputTrigger = TIM_TRGO_RESET;
  sMasterConfig.MasterOutputTrigger2 = TIM_TRGO2_RESET;
  sMasterConfig.MasterSlaveMode = TIM_MASTERSLAVEMODE_DISABLE;
  if (HAL_TIMEx_MasterConfigSynchronization(&htim1, &sMasterConfig) != HAL_OK)
  {
    Error_Handler();
  }

}

static void MX_TIM2_Init(void)
{

  TIM_Encoder_InitTypeDef sConfig = {0};
  TIM_MasterConfigTypeDef sMasterConfig = {0};

  htim2.Instance = TIM2;
  htim2.Init.Prescaler = 0;
  htim2.Init.CounterMode = TIM_COUNTERMODE_UP;
  htim2.Init.Period = 0;
  htim2.Init.ClockDivision = TIM_CLOCKDIVISION_DIV1;
  htim2.Init.AutoReloadPreload = TIM_AUTORELOAD_PRELOAD_DISABLE;
  sConfig.EncoderMode = TIM_ENCODERMODE_TI1;
  sConfig.IC1Polarity = TIM_ICPOLARITY_RISING;
  sConfig.IC1Selection = TIM_ICSELECTION_DIRECTTI;
  sConfig.IC1Prescaler = TIM_ICPSC_DIV1;
  sConfig.IC1Filter = 0;
  sConfig.IC2Polarity = TIM_ICPOLARITY_RISING;
  sConfig.IC2Selection = TIM_ICSELECTION_DIRECTTI;
  sConfig.IC2Prescaler = TIM_ICPSC_DIV1;
  sConfig.IC2Filter = 0;
  if (HAL_TIM_Encoder_Init(&htim2, &sConfig) != HAL_OK)
  {
    Error_Handler();
  }
  sMasterConfig.MasterOutputTrigger = TIM_TRGO_RESET;
  sMasterConfig.MasterSlaveMode = TIM_MASTERSLAVEMODE_DISABLE;
  if (HAL_TIMEx_MasterConfigSynchronization(&htim2, &sMasterConfig) != HAL_OK)
  {
    Error_Handler();
  }

}

static void MX_TIM3_Init(void)
{

  TIM_Encoder_InitTypeDef sConfig = {0};
  TIM_MasterConfigTypeDef sMasterConfig = {0};

  htim3.Instance = TIM3;
  htim3.Init.Prescaler = 0;
  htim3.Init.CounterMode = TIM_COUNTERMODE_UP;
  htim3.Init.Period = 0;
  htim3.Init.ClockDivision = TIM_CLOCKDIVISION_DIV1;
  htim3.Init.AutoReloadPreload = TIM_AUTORELOAD_PRELOAD_DISABLE;
  sConfig.EncoderMode = TIM_ENCODERMODE_TI1;
  sConfig.IC1Polarity = TIM_ICPOLARITY_RISING;
  sConfig.IC1Selection = TIM_ICSELECTION_DIRECTTI;
  sConfig.IC1Prescaler = TIM_ICPSC_DIV1;
  sConfig.IC1Filter = 0;
  sConfig.IC2Polarity = TIM_ICPOLARITY_RISING;
  sConfig.IC2Selection = TIM_ICSELECTION_DIRECTTI;
  sConfig.IC2Prescaler = TIM_ICPSC_DIV1;
  sConfig.IC2Filter = 0;
  if (HAL_TIM_Encoder_Init(&htim3, &sConfig) != HAL_OK)
  {
    Error_Handler();
  }
  sMasterConfig.MasterOutputTrigger = TIM_TRGO_RESET;
  sMasterConfig.MasterSlaveMode = TIM_MASTERSLAVEMODE_DISABLE;
  if (HAL_TIMEx_MasterConfigSynchronization(&htim3, &sMasterConfig) != HAL_OK)
  {
    Error_Handler();
  }

}

static void MX_TIM4_Init(void)
{

  TIM_Encoder_InitTypeDef sConfig = {0};
  TIM_MasterConfigTypeDef sMasterConfig = {0};

  htim4.Instance = TIM4;
  htim4.Init.Prescaler = 0;
  htim4.Init.CounterMode = TIM_COUNTERMODE_UP;
  htim4.Init.Period = 0;
  htim4.Init.ClockDivision = TIM_CLOCKDIVISION_DIV1;
  htim4.Init.AutoReloadPreload = TIM_AUTORELOAD_PRELOAD_DISABLE;
  sConfig.EncoderMode = TIM_ENCODERMODE_TI1;
  sConfig.IC1Polarity = TIM_ICPOLARITY_RISING;
  sConfig.IC1Selection = TIM_ICSELECTION_DIRECTTI;
  sConfig.IC1Prescaler = TIM_ICPSC_DIV1;
  sConfig.IC1Filter = 0;
  sConfig.IC2Polarity = TIM_ICPOLARITY_RISING;
  sConfig.IC2Selection = TIM_ICSELECTION_DIRECTTI;
  sConfig.IC2Prescaler = TIM_ICPSC_DIV1;
  sConfig.IC2Filter = 0;
  if (HAL_TIM_Encoder_Init(&htim4, &sConfig) != HAL_OK)
  {
    Error_Handler();
  }
  sMasterConfig.MasterOutputTrigger = TIM_TRGO_RESET;
  sMasterConfig.MasterSlaveMode = TIM_MASTERSLAVEMODE_DISABLE;
  if (HAL_TIMEx_MasterConfigSynchronization(&htim4, &sMasterConfig) != HAL_OK)
  {
    Error_Handler();
  }

}

static void MX_TIM5_Init(void)
{

  TIM_Encoder_InitTypeDef sConfig = {0};
  TIM_MasterConfigTypeDef sMasterConfig = {0};

  htim5.Instance = TIM5;
  htim5.Init.Prescaler = 0;
  htim5.Init.CounterMode = TIM_COUNTERMODE_UP;
  htim5.Init.Period = 0;
  htim5.Init.ClockDivision = TIM_CLOCKDIVISION_DIV1;
  htim5.Init.AutoReloadPreload = TIM_AUTORELOAD_PRELOAD_DISABLE;
  sConfig.EncoderMode = TIM_ENCODERMODE_TI1;
  sConfig.IC1Polarity = TIM_ICPOLARITY_RISING;
  sConfig.IC1Selection = TIM_ICSELECTION_DIRECTTI;
  sConfig.IC1Prescaler = TIM_ICPSC_DIV1;
  sConfig.IC1Filter = 0;
  sConfig.IC2Polarity = TIM_ICPOLARITY_RISING;
  sConfig.IC2Selection = TIM_ICSELECTION_DIRECTTI;
  sConfig.IC2Prescaler = TIM_ICPSC_DIV1;
  sConfig.IC2Filter = 0;
  if (HAL_TIM_Encoder_Init(&htim5, &sConfig) != HAL_OK)
  {
    Error_Handler();
  }
  sMasterConfig.MasterOutputTrigger = TIM_TRGO_RESET;
  sMasterConfig.MasterSlaveMode = TIM_MASTERSLAVEMODE_DISABLE;
  if (HAL_TIMEx_MasterConfigSynchronization(&htim5, &sMasterConfig) != HAL_OK)
  {
    Error_Handler();
  }

}

static void MX_TIM6_Init(void)
{

  TIM_MasterConfigTypeDef sMasterConfig = {0};

  htim6.Instance = TIM6;
  htim6.Init.Prescaler = 0;
  htim6.Init.CounterMode = TIM_COUNTERMODE_UP;
  htim6.Init.Period = 0;
  htim6.Init.AutoReloadPreload = TIM_AUTORELOAD_PRELOAD_DISABLE;
  if (HAL_TIM_Base_Init(&htim6) != HAL_OK)
  {
    Error_Handler();
  }
  sMasterConfig.MasterOutputTrigger = TIM_TRGO_RESET;
  sMasterConfig.MasterSlaveMode = TIM_MASTERSLAVEMODE_DISABLE;
  if (HAL_TIMEx_MasterConfigSynchronization(&htim6, &sMasterConfig) != HAL_OK)
  {
    Error_Handler();
  }

}

static void MX_TIM7_Init(void)
{

  TIM_MasterConfigTypeDef sMasterConfig = {0};

  htim7.Instance = TIM7;
  htim7.Init.Prescaler = 0;
  htim7.Init.CounterMode = TIM_COUNTERMODE_UP;
  htim7.Init.Period = 0;
  htim7.Init.AutoReloadPreload = TIM_AUTORELOAD_PRELOAD_DISABLE;
  if (HAL_TIM_Base_Init(&htim7) != HAL_OK)
  {
    Error_Handler();
  }
  sMasterConfig.MasterOutputTrigger = TIM_TRGO_RESET;
  sMasterConfig.MasterSlaveMode = TIM_MASTERSLAVEMODE_DISABLE;
  if (HAL_TIMEx_MasterConfigSynchronization(&htim7, &sMasterConfig) != HAL_OK)
  {
    Error_Handler();
  }

}

static void MX_TIM8_Init(void)
{

  TIM_Encoder_InitTypeDef sConfig = {0};
  TIM_MasterConfigTypeDef sMasterConfig = {0};

  htim8.Instance = TIM8;
  htim8.Init.Prescaler = 0;
  htim8.Init.CounterMode = TIM_COUNTERMODE_UP;
  htim8.Init.Period = 0;
  htim8.Init.ClockDivision = TIM_CLOCKDIVISION_DIV1;
  htim8.Init.RepetitionCounter = 0;
  htim8.Init.AutoReloadPreload = TIM_AUTORELOAD_PRELOAD_DISABLE;
  sConfig.EncoderMode = TIM_ENCODERMODE_TI1;
  sConfig.IC1Polarity = TIM_ICPOLARITY_RISING;
  sConfig.IC1Selection = TIM_ICSELECTION_DIRECTTI;
  sConfig.IC1Prescaler = TIM_ICPSC_DIV1;
  sConfig.IC1Filter = 0;
  sConfig.IC2Polarity = TIM_ICPOLARITY_RISING;
  sConfig.IC2Selection = TIM_ICSELECTION_DIRECTTI;
  sConfig.IC2Prescaler = TIM_ICPSC_DIV1;
  sConfig.IC2Filter = 0;
  if (HAL_TIM_Encoder_Init(&htim8, &sConfig) != HAL_OK)
  {
    Error_Handler();
  }
  sMasterConfig.MasterOutputTrigger = TIM_TRGO_RESET;
  sMasterConfig.MasterOutputTrigger2 = TIM_TRGO2_RESET;
  sMasterConfig.MasterSlaveMode = TIM_MASTERSLAVEMODE_DISABLE;
  if (HAL_TIMEx_MasterConfigSynchronization(&htim8, &sMasterConfig) != HAL_OK)
  {
    Error_Handler();
  }

}

static void MX_TIM12_Init(void)
{

  LL_TIM_InitTypeDef TIM_InitStruct = {0};

  /* Peripheral clock enable */
  LL_APB1_GRP1_EnableClock(LL_APB1_GRP1_PERIPH_TIM12);

  /* TIM12 interrupt Init */
  NVIC_SetPriority(TIM8_BRK_TIM12_IRQn, NVIC_EncodePriority(NVIC_GetPriorityGrouping(),6, 0));
  NVIC_EnableIRQ(TIM8_BRK_TIM12_IRQn);

  TIM_InitStruct.Prescaler = 0;
  TIM_InitStruct.CounterMode = LL_TIM_COUNTERMODE_UP;
  TIM_InitStruct.Autoreload = 0;
  TIM_InitStruct.ClockDivision = LL_TIM_CLOCKDIVISION_DIV1;
  LL_TIM_Init(TIM12, &TIM_InitStruct);
  LL_TIM_DisableARRPreload(TIM12);
  LL_TIM_SetClockSource(TIM12, LL_TIM_CLOCKSOURCE_INTERNAL);

}

static void MX_TIM13_Init(void)
{

  TIM_OC_InitTypeDef sConfigOC = {0};

  htim13.Instance = TIM13;
  htim13.Init.Prescaler = 0;
  htim13.Init.CounterMode = TIM_COUNTERMODE_UP;
  htim13.Init.Period = 0;
  htim13.Init.ClockDivision = TIM_CLOCKDIVISION_DIV1;
  htim13.Init.AutoReloadPreload = TIM_AUTORELOAD_PRELOAD_DISABLE;
  if (HAL_TIM_Base_Init(&htim13) != HAL_OK)
  {
    Error_Handler();
  }
  if (HAL_TIM_PWM_Init(&htim13) != HAL_OK)
  {
    Error_Handler();
  }
  sConfigOC.OCMode = TIM_OCMODE_PWM1;
  sConfigOC.Pulse = 0;
  sConfigOC.OCPolarity = TIM_OCPOLARITY_HIGH;
  sConfigOC.OCFastMode = TIM_OCFAST_DISABLE;
  if (HAL_TIM_PWM_ConfigChannel(&htim13, &sConfigOC, TIM_CHANNEL_1) != HAL_OK)
  {
    Error_Handler();
  }
  HAL_TIM_MspPostInit(&htim13);

}

static void MX_TIM14_Init(void)
{

  LL_TIM_InitTypeDef TIM_InitStruct = {0};

  /* Peripheral clock enable */
  LL_APB1_GRP1_EnableClock(LL_APB1_GRP1_PERIPH_TIM14);

  /* TIM14 interrupt Init */
  NVIC_SetPriority(TIM8_TRG_COM_TIM14_IRQn, NVIC_EncodePriority(NVIC_GetPriorityGrouping(),5, 0));
  NVIC_EnableIRQ(TIM8_TRG_COM_TIM14_IRQn);

  TIM_InitStruct.Prescaler = 0;
  TIM_InitStruct.CounterMode = LL_TIM_COUNTERMODE_UP;
  TIM_InitStruct.Autoreload = 0;
  TIM_InitStruct.ClockDivision = LL_TIM_CLOCKDIVISION_DIV1;
  LL_TIM_Init(TIM14, &TIM_InitStruct);
  LL_TIM_DisableARRPreload(TIM14);

}

static void MX_USART3_UART_Init(void)
{

  huart3.Instance = USART3;
  huart3.Init.BaudRate = 115200;
  huart3.Init.WordLength = UART_WORDLENGTH_8B;
  huart3.Init.StopBits = UART_STOPBITS_1;
  huart3.Init.Parity = UART_PARITY_NONE;
  huart3.Init.Mode = UART_MODE_TX_RX;
  huart3.Init.HwFlowCtl = UART_HWCONTROL_NONE;
  huart3.Init.OverSampling = UART_OVERSAMPLING_16;
  huart3.Init.OneBitSampling = UART_ONE_BIT_SAMPLE_DISABLE;
  huart3.Init.ClockPrescaler = UART_PRESCALER_DIV1;
  huart3.AdvancedInit.AdvFeatureInit = UART_ADVFEATURE_NO_INIT;
  if (HAL_UART_Init(&huart3) != HAL_OK)
  {
    Error_Handler();
  }
  if (HAL_UARTEx_SetTxFifoThreshold(&huart3, UART_TXFIFO_THRESHOLD_1_8) != HAL_OK)
  {
    Error_Handler();
  }
  if (HAL_UARTEx_SetRxFifoThreshold(&huart3, UART_RXFIFO_THRESHOLD_1_8) != HAL_OK)
  {
    Error_Handler();
  }
  if (HAL_UARTEx_DisableFifoMode(&huart3) != HAL_OK)
  {
    Error_Handler();
  }

}

static void MX_GPIO_Init(void)
{
  LL_EXTI_InitTypeDef EXTI_InitStruct = {0};
  LL_GPIO_InitTypeDef GPIO_InitStruct = {0};

  /* GPIO Ports Clock Enable */
  LL_AHB4_GRP1_EnableClock(LL_AHB4_GRP1_PERIPH_GPIOC);
  LL_AHB4_GRP1_EnableClock(LL_AHB4_GRP1_PERIPH_GPIOF);
  LL_AHB4_GRP1_EnableClock(LL_AHB4_GRP1_PERIPH_GPIOH);
  LL_AHB4_GRP1_EnableClock(LL_AHB4_GRP1_PERIPH_GPIOA);
  LL_AHB4_GRP1_EnableClock(LL_AHB4_GRP1_PERIPH_GPIOB);
  LL_AHB4_GRP1_EnableClock(LL_AHB4_GRP1_PERIPH_GPIOE);
  LL_AHB4_GRP1_EnableClock(LL_AHB4_GRP1_PERIPH_GPIOD);
  LL_AHB4_GRP1_EnableClock(LL_AHB4_GRP1_PERIPH_GPIOG);

  /**/
  LL_GPIO_ResetOutputPin(GPIOF, X_STEP_Pin|Y_STEP_Pin|Z_STEP_Pin|A_STEP_Pin
                          |B_STEP_Pin|C_STEP_Pin|D_STEP_Pin|E_STEP_Pin
                          |X_DIRECTION_Pin|Y_DIRECTION_Pin|Z_DIRECTION_Pin|A_DIRECTION_Pin
                          |B_DIRECTION_Pin|C_DIRECTION_Pin|D_DIRECTION_Pin|E_DIRECTION_Pin);

  /**/
  LL_GPIO_ResetOutputPin(GPIOC, TEST_PULSE_Pin|TEST_DIR_Pin);

  /**/
  LL_GPIO_ResetOutputPin(GPIOB, LD1_Pin|COOLANT_FLOOD_Pin|COOLANT_MIST_Pin|STEPPERS_DISABLE_Pin
                          |LD3_Pin);

  /**/
  LL_GPIO_ResetOutputPin(GPIOG, SPINDLE_ENABLE_Pin|SPINDLE_DIRECTION_Pin|USB_PowerSwitchOn_Pin);

  /**/
  LL_GPIO_ResetOutputPin(LD2_GPIO_Port, LD2_Pin);

  /**/
  LL_SYSCFG_SetEXTISource(LL_SYSCFG_EXTI_PORTC, LL_SYSCFG_EXTI_LINE13);

  /**/
  LL_SYSCFG_SetEXTISource(LL_SYSCFG_EXTI_PORTC, LL_SYSCFG_EXTI_LINE10);

  /**/
  LL_SYSCFG_SetEXTISource(LL_SYSCFG_EXTI_PORTC, LL_SYSCFG_EXTI_LINE11);

  /**/
  LL_SYSCFG_SetEXTISource(LL_SYSCFG_EXTI_PORTC, LL_SYSCFG_EXTI_LINE12);

  /**/
  LL_SYSCFG_SetEXTISource(LL_SYSCFG_EXTI_PORTD, LL_SYSCFG_EXTI_LINE0);

  /**/
  LL_SYSCFG_SetEXTISource(LL_SYSCFG_EXTI_PORTD, LL_SYSCFG_EXTI_LINE1);

  /**/
  LL_SYSCFG_SetEXTISource(LL_SYSCFG_EXTI_PORTD, LL_SYSCFG_EXTI_LINE2);

  /**/
  LL_SYSCFG_SetEXTISource(LL_SYSCFG_EXTI_PORTD, LL_SYSCFG_EXTI_LINE3);

  /**/
  LL_SYSCFG_SetEXTISource(LL_SYSCFG_EXTI_PORTD, LL_SYSCFG_EXTI_LINE4);

  /**/
  LL_SYSCFG_SetEXTISource(LL_SYSCFG_EXTI_PORTD, LL_SYSCFG_EXTI_LINE5);

  /**/
  LL_SYSCFG_SetEXTISource(LL_SYSCFG_EXTI_PORTD, LL_SYSCFG_EXTI_LINE6);

  /**/
  LL_SYSCFG_SetEXTISource(LL_SYSCFG_EXTI_PORTD, LL_SYSCFG_EXTI_LINE7);

  /**/
  EXTI_InitStruct.Line_0_31 = LL_EXTI_LINE_13;
  EXTI_InitStruct.Line_32_63 = LL_EXTI_LINE_NONE;
  EXTI_InitStruct.Line_64_95 = LL_EXTI_LINE_NONE;
  EXTI_InitStruct.LineCommand = ENABLE;
  EXTI_InitStruct.Mode = LL_EXTI_MODE_IT;
  EXTI_InitStruct.Trigger = LL_EXTI_TRIGGER_FALLING;
  LL_EXTI_Init(&EXTI_InitStruct);

  /**/
  EXTI_InitStruct.Line_0_31 = LL_EXTI_LINE_10;
  EXTI_InitStruct.Line_32_63 = LL_EXTI_LINE_NONE;
  EXTI_InitStruct.Line_64_95 = LL_EXTI_LINE_NONE;
  EXTI_InitStruct.LineCommand = ENABLE;
  EXTI_InitStruct.Mode = LL_EXTI_MODE_IT;
  EXTI_InitStruct.Trigger = LL_EXTI_TRIGGER_FALLING;
  LL_EXTI_Init(&EXTI_InitStruct);

  /**/
  EXTI_InitStruct.Line_0_31 = LL_EXTI_LINE_11;
  EXTI_InitStruct.Line_32_63 = LL_EXTI_LINE_NONE;
  EXTI_InitStruct.Line_64_95 = LL_EXTI_LINE_NONE;
  EXTI_InitStruct.LineCommand = ENABLE;
  EXTI_InitStruct.Mode = LL_EXTI_MODE_IT;
  EXTI_InitStruct.Trigger = LL_EXTI_TRIGGER_FALLING;
  LL_EXTI_Init(&EXTI_InitStruct);

  /**/
  EXTI_InitStruct.Line_0_31 = LL_EXTI_LINE_12;
  EXTI_InitStruct.Line_32_63 = LL_EXTI_LINE_NONE;
  EXTI_InitStruct.Line_64_95 = LL_EXTI_LINE_NONE;
  EXTI_InitStruct.LineCommand = ENABLE;
  EXTI_InitStruct.Mode = LL_EXTI_MODE_IT;
  EXTI_InitStruct.Trigger = LL_EXTI_TRIGGER_FALLING;
  LL_EXTI_Init(&EXTI_InitStruct);

  /**/
  EXTI_InitStruct.Line_0_31 = LL_EXTI_LINE_0;
  EXTI_InitStruct.Line_32_63 = LL_EXTI_LINE_NONE;
  EXTI_InitStruct.Line_64_95 = LL_EXTI_LINE_NONE;
  EXTI_InitStruct.LineCommand = ENABLE;
  EXTI_InitStruct.Mode = LL_EXTI_MODE_IT;
  EXTI_InitStruct.Trigger = LL_EXTI_TRIGGER_RISING_FALLING;
  LL_EXTI_Init(&EXTI_InitStruct);

  /**/
  EXTI_InitStruct.Line_0_31 = LL_EXTI_LINE_1;
  EXTI_InitStruct.Line_32_63 = LL_EXTI_LINE_NONE;
  EXTI_InitStruct.Line_64_95 = LL_EXTI_LINE_NONE;
  EXTI_InitStruct.LineCommand = ENABLE;
  EXTI_InitStruct.Mode = LL_EXTI_MODE_IT;
  EXTI_InitStruct.Trigger = LL_EXTI_TRIGGER_RISING_FALLING;
  LL_EXTI_Init(&EXTI_InitStruct);

  /**/
  EXTI_InitStruct.Line_0_31 = LL_EXTI_LINE_2;
  EXTI_InitStruct.Line_32_63 = LL_EXTI_LINE_NONE;
  EXTI_InitStruct.Line_64_95 = LL_EXTI_LINE_NONE;
  EXTI_InitStruct.LineCommand = ENABLE;
  EXTI_InitStruct.Mode = LL_EXTI_MODE_IT;
  EXTI_InitStruct.Trigger = LL_EXTI_TRIGGER_RISING_FALLING;
  LL_EXTI_Init(&EXTI_InitStruct);

  /**/
  EXTI_InitStruct.Line_0_31 = LL_EXTI_LINE_3;
  EXTI_InitStruct.Line_32_63 = LL_EXTI_LINE_NONE;
  EXTI_InitStruct.Line_64_95 = LL_EXTI_LINE_NONE;
  EXTI_InitStruct.LineCommand = ENABLE;
  EXTI_InitStruct.Mode = LL_EXTI_MODE_IT;
  EXTI_InitStruct.Trigger = LL_EXTI_TRIGGER_RISING_FALLING;
  LL_EXTI_Init(&EXTI_InitStruct);

  /**/
  EXTI_InitStruct.Line_0_31 = LL_EXTI_LINE_4;
  EXTI_InitStruct.Line_32_63 = LL_EXTI_LINE_NONE;
  EXTI_InitStruct.Line_64_95 = LL_EXTI_LINE_NONE;
  EXTI_InitStruct.LineCommand = ENABLE;
  EXTI_InitStruct.Mode = LL_EXTI_MODE_IT;
  EXTI_InitStruct.Trigger = LL_EXTI_TRIGGER_RISING_FALLING;
  LL_EXTI_Init(&EXTI_InitStruct);

  /**/
  EXTI_InitStruct.Line_0_31 = LL_EXTI_LINE_5;
  EXTI_InitStruct.Line_32_63 = LL_EXTI_LINE_NONE;
  EXTI_InitStruct.Line_64_95 = LL_EXTI_LINE_NONE;
  EXTI_InitStruct.LineCommand = ENABLE;
  EXTI_InitStruct.Mode = LL_EXTI_MODE_IT;
  EXTI_InitStruct.Trigger = LL_EXTI_TRIGGER_RISING_FALLING;
  LL_EXTI_Init(&EXTI_InitStruct);

  /**/
  EXTI_InitStruct.Line_0_31 = LL_EXTI_LINE_6;
  EXTI_InitStruct.Line_32_63 = LL_EXTI_LINE_NONE;
  EXTI_InitStruct.Line_64_95 = LL_EXTI_LINE_NONE;
  EXTI_InitStruct.LineCommand = ENABLE;
  EXTI_InitStruct.Mode = LL_EXTI_MODE_IT;
  EXTI_InitStruct.Trigger = LL_EXTI_TRIGGER_RISING;
  LL_EXTI_Init(&EXTI_InitStruct);

  /**/
  EXTI_InitStruct.Line_0_31 = LL_EXTI_LINE_7;
  EXTI_InitStruct.Line_32_63 = LL_EXTI_LINE_NONE;
  EXTI_InitStruct.Line_64_95 = LL_EXTI_LINE_NONE;
  EXTI_InitStruct.LineCommand = ENABLE;
  EXTI_InitStruct.Mode = LL_EXTI_MODE_IT;
  EXTI_InitStruct.Trigger = LL_EXTI_TRIGGER_RISING;
  LL_EXTI_Init(&EXTI_InitStruct);

  /**/
  LL_GPIO_SetPinPull(B1_RESET_GRBL_GPIO_Port, B1_RESET_GRBL_Pin, LL_GPIO_PULL_NO);

  /**/
  LL_GPIO_SetPinPull(SAFETY_DOOR_GPIO_Port, SAFETY_DOOR_Pin, LL_GPIO_PULL_UP);

  /**/
  LL_GPIO_SetPinPull(FEED_HOLD_GPIO_Port, FEED_HOLD_Pin, LL_GPIO_PULL_UP);

  /**/
  LL_GPIO_SetPinPull(CYCLE_START_GPIO_Port, CYCLE_START_Pin, LL_GPIO_PULL_UP);

  /**/
  LL_GPIO_SetPinPull(X_LIMIT_GPIO_Port, X_LIMIT_Pin, LL_GPIO_PULL_UP);

  /**/
  LL_GPIO_SetPinPull(Y_LIMIT_GPIO_Port, Y_LIMIT_Pin, LL_GPIO_PULL_UP);

  /**/
  LL_GPIO_SetPinPull(Z_LIMIT_GPIO_Port, Z_LIMIT_Pin, LL_GPIO_PULL_UP);

  /**/
  LL_GPIO_SetPinPull(A_LIMIT_GPIO_Port, A_LIMIT_Pin, LL_GPIO_PULL_UP);

  /**/
  LL_GPIO_SetPinPull(B_LIMIT_GPIO_Port, B_LIMIT_Pin, LL_GPIO_PULL_UP);

  /**/
  LL_GPIO_SetPinPull(C_LIMIT_GPIO_Port, C_LIMIT_Pin, LL_GPIO_PULL_UP);

  /**/
  LL_GPIO_SetPinPull(D_LIMIT_GPIO_Port, D_LIMIT_Pin, LL_GPIO_PULL_UP);

  /**/
  LL_GPIO_SetPinPull(E_LIMIT_GPIO_Port, E_LIMIT_Pin, LL_GPIO_PULL_UP);

  /**/
  GPIO_InitStruct.Pin = X_STEP_Pin|Y_STEP_Pin|Z_STEP_Pin|A_STEP_Pin
                          |B_STEP_Pin|C_STEP_Pin|D_STEP_Pin|E_STEP_Pin
                          |X_DIRECTION_Pin|Y_DIRECTION_Pin|Z_DIRECTION_Pin|A_DIRECTION_Pin
                          |B_DIRECTION_Pin|C_DIRECTION_Pin|D_DIRECTION_Pin|E_DIRECTION_Pin;
  GPIO_InitStruct.Mode = LL_GPIO_MODE_OUTPUT;
  GPIO_InitStruct.Speed = LL_GPIO_SPEED_FREQ_VERY_HIGH;
  GPIO_InitStruct.OutputType = LL_GPIO_OUTPUT_PUSHPULL;
  GPIO_InitStruct.Pull = LL_GPIO_PULL_NO;
  LL_GPIO_Init(GPIOF, &GPIO_InitStruct);

  /**/
  GPIO_InitStruct.Pin = TEST_PULSE_Pin|TEST_DIR_Pin;
  GPIO_InitStruct.Mode = LL_GPIO_MODE_OUTPUT;
  GPIO_InitStruct.Speed = LL_GPIO_SPEED_FREQ_VERY_HIGH;
  GPIO_InitStruct.OutputType = LL_GPIO_OUTPUT_PUSHPULL;
  GPIO_InitStruct.Pull = LL_GPIO_PULL_NO;
  LL_GPIO_Init(GPIOC, &GPIO_InitStruct);

  /**/
  GPIO_InitStruct.Pin = RMII_MDC_Pin|RMII_RXD0_Pin|RMII_RXD1_Pin;
  GPIO_InitStruct.Mode = LL_GPIO_MODE_ALTERNATE;
  GPIO_InitStruct.Speed = LL_GPIO_SPEED_FREQ_LOW;
  GPIO_InitStruct.OutputType = LL_GPIO_OUTPUT_PUSHPULL;
  GPIO_InitStruct.Pull = LL_GPIO_PULL_NO;
  GPIO_InitStruct.Alternate = LL_GPIO_AF_11;
  LL_GPIO_Init(GPIOC, &GPIO_InitStruct);

  /**/
  GPIO_InitStruct.Pin = RMII_MDIO_Pin|RMII_CRS_DV_Pin;
  GPIO_InitStruct.Mode = LL_GPIO_MODE_ALTERNATE;
  GPIO_InitStruct.Speed = LL_GPIO_SPEED_FREQ_LOW;
  GPIO_InitStruct.OutputType = LL_GPIO_OUTPUT_PUSHPULL;
  GPIO_InitStruct.Pull = LL_GPIO_PULL_NO;
  GPIO_InitStruct.Alternate = LL_GPIO_AF_11;
  LL_GPIO_Init(GPIOA, &GPIO_InitStruct);

  /**/
  GPIO_InitStruct.Pin = LD1_Pin|COOLANT_FLOOD_Pin|COOLANT_MIST_Pin|STEPPERS_DISABLE_Pin
                          |LD3_Pin;
  GPIO_InitStruct.Mode = LL_GPIO_MODE_OUTPUT;
  GPIO_InitStruct.Speed = LL_GPIO_SPEED_FREQ_VERY_HIGH;
  GPIO_InitStruct.OutputType = LL_GPIO_OUTPUT_PUSHPULL;
  GPIO_InitStruct.Pull = LL_GPIO_PULL_NO;
  LL_GPIO_Init(GPIOB, &GPIO_InitStruct);

  /**/
  GPIO_InitStruct.Pin = RMII_TXD1_Pin;
  GPIO_InitStruct.Mode = LL_GPIO_MODE_ALTERNATE;
  GPIO_InitStruct.Speed = LL_GPIO_SPEED_FREQ_LOW;
  GPIO_InitStruct.OutputType = LL_GPIO_OUTPUT_PUSHPULL;
  GPIO_InitStruct.Pull = LL_GPIO_PULL_NO;
  GPIO_InitStruct.Alternate = LL_GPIO_AF_11;
  LL_GPIO_Init(RMII_TXD1_GPIO_Port, &GPIO_InitStruct);

  /**/
  GPIO_InitStruct.Pin = SPINDLE_ENABLE_Pin|SPINDLE_DIRECTION_Pin|USB_PowerSwitchOn_Pin;
  GPIO_InitStruct.Mode = LL_GPIO_MODE_OUTPUT;
  GPIO_InitStruct.Speed = LL_GPIO_SPEED_FREQ_VERY_HIGH;
  GPIO_InitStruct.OutputType = LL_GPIO_OUTPUT_PUSHPULL;
  GPIO_InitStruct.Pull = LL_GPIO_PULL_NO;
  LL_GPIO_Init(GPIOG, &GPIO_InitStruct);

  /**/
  GPIO_InitStruct.Pin = USB_OverCurrent_Pin;
  GPIO_InitStruct.Mode = LL_GPIO_MODE_INPUT;
  GPIO_InitStruct.Pull = LL_GPIO_PULL_NO;
  LL_GPIO_Init(USB_OverCurrent_GPIO_Port, &GPIO_InitStruct);

  /**/
  GPIO_InitStruct.Pin = USB_SOF_Pin|USB_DM_Pin|USB_DP_Pin;
  GPIO_InitStruct.Mode = LL_GPIO_MODE_ALTERNATE;
  GPIO_InitStruct.Speed = LL_GPIO_SPEED_FREQ_VERY_HIGH;
  GPIO_InitStruct.OutputType = LL_GPIO_OUTPUT_PUSHPULL;
  GPIO_InitStruct.Pull = LL_GPIO_PULL_NO;
  GPIO_InitStruct.Alternate = LL_GPIO_AF_10;
  LL_GPIO_Init(GPIOA, &GPIO_InitStruct);

  /**/
  GPIO_InitStruct.Pin = USB_ID_Pin;
  GPIO_InitStruct.Mode = LL_GPIO_MODE_ALTERNATE;
  GPIO_InitStruct.Speed = LL_GPIO_SPEED_FREQ_LOW;
  GPIO_InitStruct.OutputType = LL_GPIO_OUTPUT_PUSHPULL;
  GPIO_InitStruct.Pull = LL_GPIO_PULL_NO;
  GPIO_InitStruct.Alternate = LL_GPIO_AF_10;
  LL_GPIO_Init(USB_ID_GPIO_Port, &GPIO_InitStruct);

  /**/
  GPIO_InitStruct.Pin = PROBE_Pin;
  GPIO_InitStruct.Mode = LL_GPIO_MODE_INPUT;
  GPIO_InitStruct.Pull = LL_GPIO_PULL_UP;
  LL_GPIO_Init(PROBE_GPIO_Port, &GPIO_InitStruct);

  /**/
  GPIO_InitStruct.Pin = RMII_TX_EN_Pin|RMII_TXD0_Pin;
  GPIO_InitStruct.Mode = LL_GPIO_MODE_ALTERNATE;
  GPIO_InitStruct.Speed = LL_GPIO_SPEED_FREQ_LOW;
  GPIO_InitStruct.OutputType = LL_GPIO_OUTPUT_PUSHPULL;
  GPIO_InitStruct.Pull = LL_GPIO_PULL_NO;
  GPIO_InitStruct.Alternate = LL_GPIO_AF_11;
  LL_GPIO_Init(GPIOG, &GPIO_InitStruct);

  /**/
  GPIO_InitStruct.Pin = LD2_Pin;
  GPIO_InitStruct.Mode = LL_GPIO_MODE_OUTPUT;
  GPIO_InitStruct.Speed = LL_GPIO_SPEED_FREQ_LOW;
  GPIO_InitStruct.OutputType = LL_GPIO_OUTPUT_PUSHPULL;
  GPIO_InitStruct.Pull = LL_GPIO_PULL_NO;
  LL_GPIO_Init(LD2_GPIO_Port, &GPIO_InitStruct);

  /* EXTI interrupt init*/
  NVIC_SetPriority(EXTI0_IRQn, NVIC_EncodePriority(NVIC_GetPriorityGrouping(),1, 0));
  NVIC_EnableIRQ(EXTI0_IRQn);
  NVIC_SetPriority(EXTI1_IRQn, NVIC_EncodePriority(NVIC_GetPriorityGrouping(),1, 0));
  NVIC_EnableIRQ(EXTI1_IRQn);
  NVIC_SetPriority(EXTI2_IRQn, NVIC_EncodePriority(NVIC_GetPriorityGrouping(),1, 0));
  NVIC_EnableIRQ(EXTI2_IRQn);
  NVIC_SetPriority(EXTI3_IRQn, NVIC_EncodePriority(NVIC_GetPriorityGrouping(),1, 0));
  NVIC_EnableIRQ(EXTI3_IRQn);
  NVIC_SetPriority(EXTI4_IRQn, NVIC_EncodePriority(NVIC_GetPriorityGrouping(),1, 0));
  NVIC_EnableIRQ(EXTI4_IRQn);
  NVIC_SetPriority(EXTI9_5_IRQn, NVIC_EncodePriority(NVIC_GetPriorityGrouping(),1, 0));
  NVIC_EnableIRQ(EXTI9_5_IRQn);
  NVIC_SetPriority(EXTI15_10_IRQn, NVIC_EncodePriority(NVIC_GetPriorityGrouping(),8, 0));
  NVIC_EnableIRQ(EXTI15_10_IRQn);

}

/* MPU Configuration */

void MPU_Config(void)
{

  /* Disables the MPU */
  LL_MPU_Disable();
  /** Initializes and configures the Region and the memory to be protected
  */
  LL_MPU_ConfigRegion(LL_MPU_REGION_NUMBER0, 0x0, 0x38800000, LL_MPU_REGION_SIZE_4KB|LL_MPU_REGION_PRIV_RW_URO|LL_MPU_INSTRUCTION_ACCESS_ENABLE|LL_MPU_ACCESS_SHAREABLE|LL_MPU_ACCESS_CACHEABLE|LL_MPU_ACCESS_BUFFERABLE);
  LL_MPU_EnableRegion(LL_MPU_REGION_NUMBER0);
  /* Enables the MPU */
  LL_MPU_Enable(LL_MPU_CTRL_HFNMI_PRIVDEF);

}

void Error_Handler(void)
{
  while(1)
  {
  }
}

/************************ (C) COPYRIGHT STMicroelectronics *****END OF FILE****/
